# MCU_CTRL_MMR0_CFG0 register map
Vendor: Texas Instruments
Registers are 32-bit, read-write, reset 0x0 unless marked. A register's access mark holds for its fields unless they carry their own. Offsets are as the file gives them; [hi:lo] are bit positions; lines under a group give offsets from that group; {n}, {i} and the like mark numbered series.

## MCU_CTRL_MMR0_CFG0 (part 2 of 2)
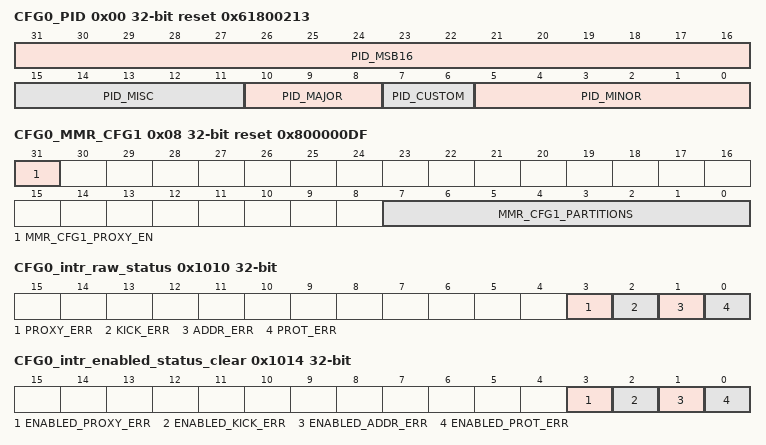
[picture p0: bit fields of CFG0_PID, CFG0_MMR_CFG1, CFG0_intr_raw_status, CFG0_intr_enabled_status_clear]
0x00 CFG0_PID ro reset 0x61800213
  [31:16] PID_MSB16, [15:11] PID_MISC, [10:8] PID_MAJOR, [7:6] PID_CUSTOM, [5:0] PID_MINOR
0x08 CFG0_MMR_CFG1 ro reset 0x800000DF
  [31] MMR_CFG1_PROXY_EN — Proxy addressing actived
  [7:0] MMR_CFG1_PARTITIONS — Indicates present partitions
{0x1008+0x4000*i} CFG0_LOCK{i}_KICK0 (i=0..4)
  [31:0] LOCK{i}_KICK0 — - KICK0 component
{0x100C+0x4000*i} CFG0_LOCK{i}_KICK1 (i=0..4)
  [31:0] LOCK{i}_KICK1 — - KICK1 component
0x1010 CFG0_intr_raw_status access not given
  [3] PROXY_ERR — Proxy0 access violation error. Raw status is read. Write a 1 to set the status. Writing a 0 has no effect. (access R/W1TS)
  [2] KICK_ERR — Kick access violation error. Raw status is read. Write a 1 to set the status. Writing a 0 has no effect. (access R/W1TS)
  [1] ADDR_ERR — Addressing violation error. Raw status is read. Write a 1 to set the status. Writing a 0 has no effect. (access R/W1TS)
  [0] PROT_ERR — Protection violation error. Raw status is read. Write a 1 to set the status. Writing a 0 has no effect. (access R/W1TS)
0x1014 CFG0_intr_enabled_status_clear access not given
  [3] ENABLED_PROXY_ERR — Proxy0 access violation error. Enabled status is read. Write a 1 to clear the status. Writing a 0 has no effect. (access R/W1TC)
  [2] ENABLED_KICK_ERR — Kick access violation error. Enabled status is read. Write a 1 to clear the status. Writing a 0 has no effect. (access R/W1TC)
  [1] ENABLED_ADDR_ERR — Addressing violation error. Enabled status is read. Write a 1 to clear the status. Writing a 0 has no effect. (access R/W1TC)
  [0] ENABLED_PROT_ERR — Protection violation error. Enabled status is read. Write a 1 to clear the status. Writing a 0 has no effect. (access R/W1TC)
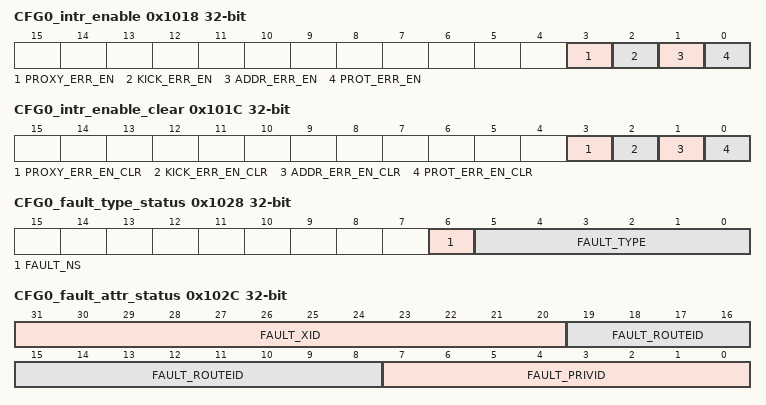
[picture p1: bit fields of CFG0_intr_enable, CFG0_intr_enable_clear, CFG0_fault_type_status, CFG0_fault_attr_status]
0x1018 CFG0_intr_enable access not given
  [3] PROXY_ERR_EN — Proxy0 access violation error enable. Write a 1 to set the enable. Writing a 0 has no effect. (access R/W1TS)
  [2] KICK_ERR_EN — Kick access violation error enable. Write a 1 to set the enable. Writing a 0 has no effect. (access R/W1TS)
  [1] ADDR_ERR_EN — Addressing violation error enable. Write a 1 to set the enable. Writing a 0 has no effect. (access R/W1TS)
  [0] PROT_ERR_EN — Protection violation error enable. Write a 1 to set the enable. Writing a 0 has no effect. (access R/W1TS)
0x101C CFG0_intr_enable_clear access not given
  [3] PROXY_ERR_EN_CLR — Proxy0 access violation error enable clear. Write a 1 to clear the enable. Writing a 0 has no effect. (access R/W1TC)
  [2] KICK_ERR_EN_CLR — Kick access violation error enable clear. Write a 1 to clear the enable. Writing a 0 has no effect. (access R/W1TC)
  [1] ADDR_ERR_EN_CLR — Addressing violation error enable clear. Write a 1 to clear the enable. Writing a 0 has no effect. (access R/W1TC)
  [0] PROT_ERR_EN_CLR — Protection violation error enable clear. Write a 1 to clear the enable. Writing a 0 has no effect. (access R/W1TC)
0x1020 CFG0_eoi
  [7:0] EOI_VECTOR — EOI vector value. Write this with interrupt distribution value in the chip.
0x1024 CFG0_fault_address ro
  [31:0] FAULT_ADDR — Fault Address.
0x1028 CFG0_fault_type_status ro
  [6] FAULT_NS — Non-secure access.
  [5:0] FAULT_TYPE — Fault Type 10_0000 = Supervisor read fault - priv = 1 dir = 1 dtype != 1 01_0000 = Supervisor write fault - priv = 1 dir = 0 00_1000 = Supervisor execute fault - priv = 1 dir = 1 dtype = 1 00_0100 = User read fault - priv = 0 dir = 1 dtype = 1 00_0010 = User write fault - priv = 0 dir = 0 00_0001 = User execute fault - priv = 0 dir = 1 dtype = 1 00_0000 = No fault
0x102C CFG0_fault_attr_status ro
  [31:20] FAULT_XID — XID.
  [19:8] FAULT_ROUTEID — Route ID.
  [7:0] FAULT_PRIVID — Privilege ID.
0x1030 CFG0_fault_clear wo
  [0] FAULT_CLR — Fault clear. Writing a 1 clears the current fault. Writing a 0 has no effect.
0x1100 CFG0_CLAIMREG_P0_R0_READONLY ro
  [31:0] CLAIMREG_P0_R0_READONLY — Claim bits for Partition 0
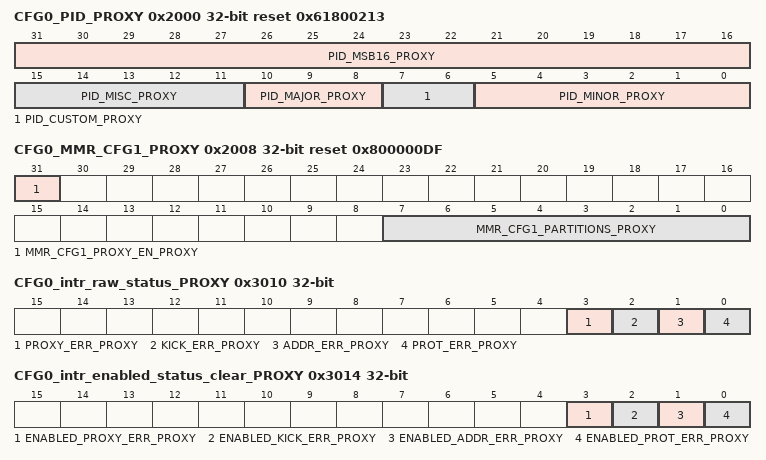
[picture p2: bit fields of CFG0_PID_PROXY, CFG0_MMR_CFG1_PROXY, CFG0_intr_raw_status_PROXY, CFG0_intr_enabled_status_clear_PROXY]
0x2000 CFG0_PID_PROXY ro reset 0x61800213
  [31:16] PID_MSB16_PROXY, [15:11] PID_MISC_PROXY, [10:8] PID_MAJOR_PROXY, [7:6] PID_CUSTOM_PROXY, [5:0] PID_MINOR_PROXY
0x2008 CFG0_MMR_CFG1_PROXY ro reset 0x800000DF
  [31] MMR_CFG1_PROXY_EN_PROXY — Proxy addressing actived
  [7:0] MMR_CFG1_PARTITIONS_PROXY — Indicates present partitions
{0x3008+0x4000*i} CFG0_LOCK{i}_KICK0_PROXY (i=0..4)
  [31:0] LOCK{i}_KICK0_PROXY — - KICK0 component
{0x300C+0x4000*i} CFG0_LOCK{i}_KICK1_PROXY (i=0..4)
  [31:0] LOCK{i}_KICK1_PROXY — - KICK1 component
0x3010 CFG0_intr_raw_status_PROXY access not given
  [3] PROXY_ERR_PROXY — Proxy0 access violation error. Raw status is read. Write a 1 to set the status. Writing a 0 has no effect. (access R/W1TS)
  [2] KICK_ERR_PROXY — Kick access violation error. Raw status is read. Write a 1 to set the status. Writing a 0 has no effect. (access R/W1TS)
  [1] ADDR_ERR_PROXY — Addressing violation error. Raw status is read. Write a 1 to set the status. Writing a 0 has no effect. (access R/W1TS)
  [0] PROT_ERR_PROXY — Protection violation error. Raw status is read. Write a 1 to set the status. Writing a 0 has no effect. (access R/W1TS)
0x3014 CFG0_intr_enabled_status_clear_PROXY access not given
  [3] ENABLED_PROXY_ERR_PROXY — Proxy0 access violation error. Enabled status is read. Write a 1 to clear the status. Writing a 0 has no effect. (access R/W1TC)
  [2] ENABLED_KICK_ERR_PROXY — Kick access violation error. Enabled status is read. Write a 1 to clear the status. Writing a 0 has no effect. (access R/W1TC)
  [1] ENABLED_ADDR_ERR_PROXY — Addressing violation error. Enabled status is read. Write a 1 to clear the status. Writing a 0 has no effect. (access R/W1TC)
  [0] ENABLED_PROT_ERR_PROXY — Protection violation error. Enabled status is read. Write a 1 to clear the status. Writing a 0 has no effect. (access R/W1TC)
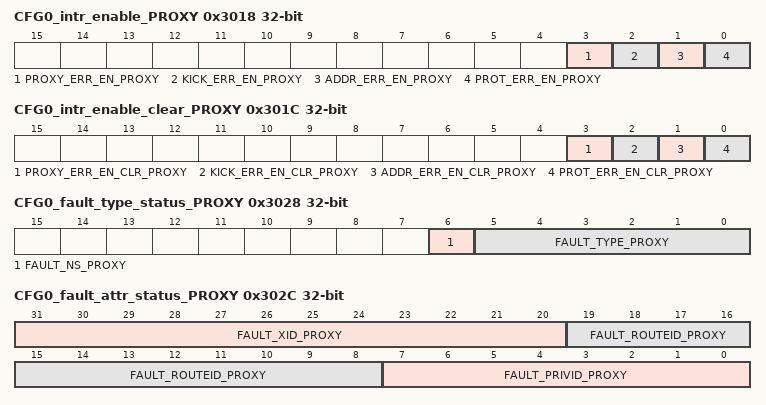
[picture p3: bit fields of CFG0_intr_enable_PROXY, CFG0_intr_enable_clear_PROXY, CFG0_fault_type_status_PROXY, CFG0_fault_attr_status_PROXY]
0x3018 CFG0_intr_enable_PROXY access not given
  [3] PROXY_ERR_EN_PROXY — Proxy0 access violation error enable. Write a 1 to set the enable. Writing a 0 has no effect. (access R/W1TS)
  [2] KICK_ERR_EN_PROXY — Kick access violation error enable. Write a 1 to set the enable. Writing a 0 has no effect. (access R/W1TS)
  [1] ADDR_ERR_EN_PROXY — Addressing violation error enable. Write a 1 to set the enable. Writing a 0 has no effect. (access R/W1TS)
  [0] PROT_ERR_EN_PROXY — Protection violation error enable. Write a 1 to set the enable. Writing a 0 has no effect. (access R/W1TS)
0x301C CFG0_intr_enable_clear_PROXY access not given
  [3] PROXY_ERR_EN_CLR_PROXY — Proxy0 access violation error enable clear. Write a 1 to clear the enable. Writing a 0 has no effect. (access R/W1TC)
  [2] KICK_ERR_EN_CLR_PROXY — Kick access violation error enable clear. Write a 1 to clear the enable. Writing a 0 has no effect. (access R/W1TC)
  [1] ADDR_ERR_EN_CLR_PROXY — Addressing violation error enable clear. Write a 1 to clear the enable. Writing a 0 has no effect. (access R/W1TC)
  [0] PROT_ERR_EN_CLR_PROXY — Protection violation error enable clear. Write a 1 to clear the enable. Writing a 0 has no effect. (access R/W1TC)
0x3020 CFG0_eoi_PROXY
  [7:0] EOI_VECTOR_PROXY — EOI vector value. Write this with interrupt distribution value in the chip.
0x3024 CFG0_fault_address_PROXY ro
  [31:0] FAULT_ADDR_PROXY — Fault Address.
0x3028 CFG0_fault_type_status_PROXY ro
  [6] FAULT_NS_PROXY — Non-secure access.
  [5:0] FAULT_TYPE_PROXY — Fault Type 10_0000 = Supervisor read fault - priv = 1 dir = 1 dtype != 1 01_0000 = Supervisor write fault - priv = 1 dir = 0 00_1000 = Supervisor execute fault - priv = 1 dir = 1 dtype = 1 00_0100 = User read fault - priv = 0 dir = 1 dtype = 1 00_0010 = User write fault - priv = 0 dir = 0 00_0001 = User execute fault - priv = 0 dir = 1 dtype = 1 00_0000 = No fault
0x302C CFG0_fault_attr_status_PROXY ro
  [31:20] FAULT_XID_PROXY — XID.
  [19:8] FAULT_ROUTEID_PROXY — Route ID.
  [7:0] FAULT_PRIVID_PROXY — Privilege ID.
0x3030 CFG0_fault_clear_PROXY wo
  [0] FAULT_CLR_PROXY — Fault clear. Writing a 1 clears the current fault. Writing a 0 has no effect.
0x3100 CFG0_CLAIMREG_P0_R0
  [31:0] CLAIMREG_P0_R0 — Claim bits for Partition 0
{0x4080+4i} CFG0_DBOUNCE_CFG{i} (i=1..6)
  [5:0] DBOUNCE_CFG{i}_DB_CFG — Configures the debounce period used for I/Os with debounce_sel{i} actived. See the AM64xx IO Integration Spec for Detail (https://pds.design.ti.com/cgi-bin/viewdocs?pds_bgid=21&docconfigid=736&filtertitle=2622&filteritem=13912)
0x40A0 CFG0_TEMP_DIODE_TRIM ro
  [13:0] TEMP_DIODE_TRIM_TRIM — Sets the diode non-ideality factor (n), starting from 100th place decimal and going down
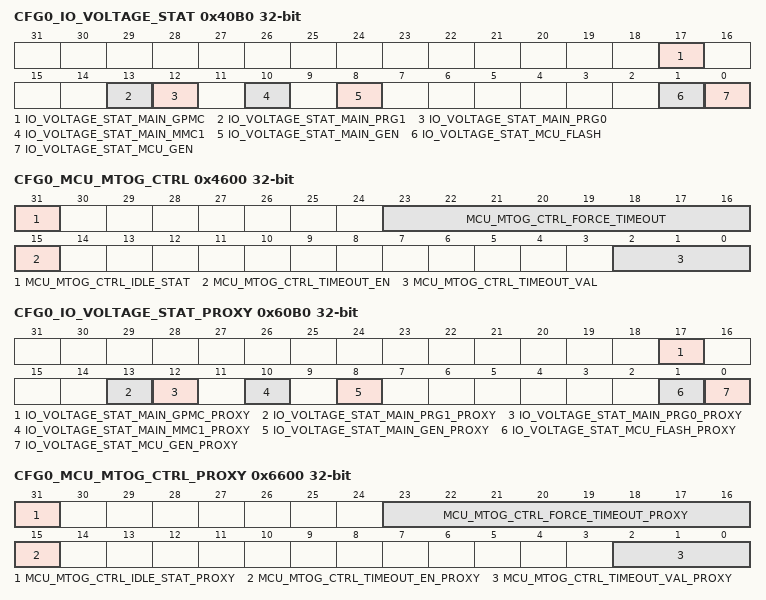
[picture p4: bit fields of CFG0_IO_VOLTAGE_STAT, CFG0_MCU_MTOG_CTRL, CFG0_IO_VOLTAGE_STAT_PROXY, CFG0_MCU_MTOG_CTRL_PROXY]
0x40B0 CFG0_IO_VOLTAGE_STAT ro
  [17] IO_VOLTAGE_STAT_MAIN_GPMC — Indicates the voltage for the GPMC I/O group (VDDSHV3)
  [13] IO_VOLTAGE_STAT_MAIN_PRG1 — Indicates the voltage for the PRG1 I/O group (VDDSHV1)
  [12] IO_VOLTAGE_STAT_MAIN_PRG0 — Indicates the voltage for the PRG0 I/O group (VDDSHV2)
  [10] IO_VOLTAGE_STAT_MAIN_MMC1 — Indicates the voltage for the MMC1 I/O group (VDDSHV5)
  [8] IO_VOLTAGE_STAT_MAIN_GEN — Indicates the voltage for the General I/O group (VDDSHV0)
  [1] IO_VOLTAGE_STAT_MCU_FLASH — Indicates the voltage for the Flash I/O group (VDDSHV4)
  [0] IO_VOLTAGE_STAT_MCU_GEN — Indicates the voltage for the MCU General I/O group (VDDSHV0_MCU)
0x4204 CFG0_MCU_TIMER1_CTRL
  [8] MCU_TIMER1_CTRL_CASCADE_EN — Actives cascading of TIMER1 to TIMER0
0x420C CFG0_MCU_TIMER3_CTRL
  [8] MCU_TIMER3_CTRL_CASCADE_EN — Actives cascading of TIMER3 to TIMER2
0x42E0 CFG0_MCU_I2C0_CTRL
  [0] MCU_I2C0_CTRL_HS_MCS_EN — HS Mode controller current source active.
0x4600 CFG0_MCU_MTOG_CTRL access per field
  [31] MCU_MTOG_CTRL_IDLE_STAT ro — Idle Status:
  [23:16] MCU_MTOG_CTRL_FORCE_TIMEOUT rw — Force Timout
  [15] MCU_MTOG_CTRL_TIMEOUT_EN rw — Timeout Active
  [2:0] MCU_MTOG_CTRL_TIMEOUT_VAL rw — Gasket Timeout Value
{0x5100+4i} CFG0_CLAIMREG_P1_R{i}_READONLY ro (i=0..12)
  [31:0] CLAIMREG_P1_R{i}_READONLY — Claim bits for Partition 1
{0x6080+4i} CFG0_DBOUNCE_CFG{i}_PROXY (i=1..6)
  [5:0] DBOUNCE_CFG{i}_DB_CFG_PROXY — Configures the debounce period used for I/Os with debounce_sel{i} actived. See the AM64xx IO Integration Spec for Detail (https://pds.design.ti.com/cgi-bin/viewdocs?pds_bgid=21&docconfigid=736&filtertitle=2622&filteritem=13912)
0x60A0 CFG0_TEMP_DIODE_TRIM_PROXY ro
  [13:0] TEMP_DIODE_TRIM_TRIM_PROXY — Sets the diode non-ideality factor (n), starting from 100th place decimal and going down
0x60B0 CFG0_IO_VOLTAGE_STAT_PROXY ro
  [17] IO_VOLTAGE_STAT_MAIN_GPMC_PROXY — Indicates the voltage for the GPMC I/O group (VDDSHV3)
  [13] IO_VOLTAGE_STAT_MAIN_PRG1_PROXY — Indicates the voltage for the PRG1 I/O group (VDDSHV1)
  [12] IO_VOLTAGE_STAT_MAIN_PRG0_PROXY — Indicates the voltage for the PRG0 I/O group (VDDSHV2)
  [10] IO_VOLTAGE_STAT_MAIN_MMC1_PROXY — Indicates the voltage for the MMC1 I/O group (VDDSHV5)
  [8] IO_VOLTAGE_STAT_MAIN_GEN_PROXY — Indicates the voltage for the General I/O group (VDDSHV0)
  [1] IO_VOLTAGE_STAT_MCU_FLASH_PROXY — Indicates the voltage for the Flash I/O group (VDDSHV4)
  [0] IO_VOLTAGE_STAT_MCU_GEN_PROXY — Indicates the voltage for the MCU General I/O group (VDDSHV0_MCU)
0x6204 CFG0_MCU_TIMER1_CTRL_PROXY
  [8] MCU_TIMER1_CTRL_CASCADE_EN_PROXY — Actives cascading of TIMER1 to TIMER0
0x620C CFG0_MCU_TIMER3_CTRL_PROXY
  [8] MCU_TIMER3_CTRL_CASCADE_EN_PROXY — Actives cascading of TIMER3 to TIMER2
0x62E0 CFG0_MCU_I2C0_CTRL_PROXY
  [0] MCU_I2C0_CTRL_HS_MCS_EN_PROXY — HS Mode controller current source active.
0x6600 CFG0_MCU_MTOG_CTRL_PROXY access per field
  [31] MCU_MTOG_CTRL_IDLE_STAT_PROXY ro — Idle Status:
  [23:16] MCU_MTOG_CTRL_FORCE_TIMEOUT_PROXY rw — Force Timout
  [15] MCU_MTOG_CTRL_TIMEOUT_EN_PROXY rw — Timeout Active
  [2:0] MCU_MTOG_CTRL_TIMEOUT_VAL_PROXY rw — Gasket Timeout Value
{0x7100+4i} CFG0_CLAIMREG_P1_R{i} (i=0..12)
  [31:0] CLAIMREG_P1_R{i} — Claim bits for Partition 1
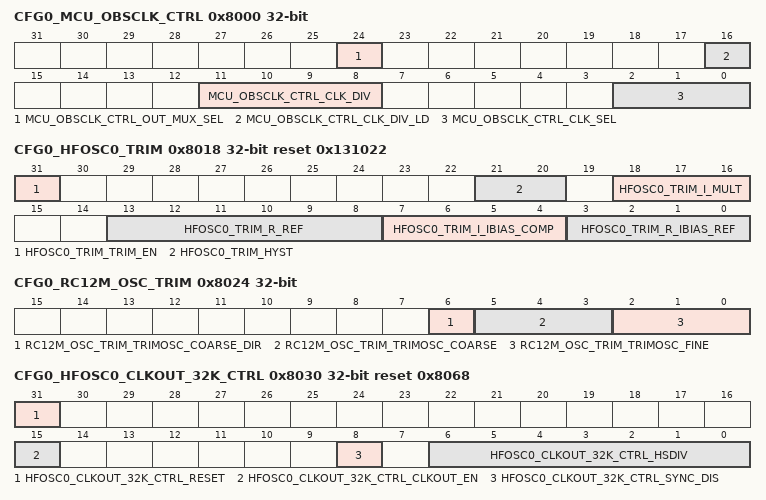
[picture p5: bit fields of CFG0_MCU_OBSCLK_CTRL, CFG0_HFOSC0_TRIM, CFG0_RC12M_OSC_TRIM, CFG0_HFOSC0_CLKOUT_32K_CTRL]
0x8000 CFG0_MCU_OBSCLK_CTRL
  [24] MCU_OBSCLK_CTRL_OUT_MUX_SEL — MCU_OBSCLK pin output mux selection.
  [16] MCU_OBSCLK_CTRL_CLK_DIV_LD — Load the output divider value
  [11:8] MCU_OBSCLK_CTRL_CLK_DIV — MCU_OBSCLK pin clock selection output divider
  [2:0] MCU_OBSCLK_CTRL_CLK_SEL — MCU_OBSCLK pin clock selection
0x8010 CFG0_HFOSC0_CTRL
  [4] HFOSC0_CTRL_BP_C — Oscillator bypass control. When set oscillator is in bypass mode
0x8018 CFG0_HFOSC0_TRIM reset 0x131022
  [31] HFOSC0_TRIM_TRIM_EN — Apply MMR values to OSC trim inputs instead of tie-offs
  [21:20] HFOSC0_TRIM_HYST — Sets comparator hysterisis
  [18:16] HFOSC0_TRIM_I_MULT — AGC AMP current multiplication gain
  [13:8] HFOSC0_TRIM_R_REF — Sets the AMP AGC bias current
  [7:4] HFOSC0_TRIM_I_IBIAS_COMP — Sets the COMP bias current
  [3:0] HFOSC0_TRIM_R_IBIAS_REF — Sets the base IBIAS reference
0x8024 CFG0_RC12M_OSC_TRIM
  [6] RC12M_OSC_TRIM_TRIMOSC_COARSE_DIR — Coarse adjustment direction. If output is greater than 12.5
  [5:3] RC12M_OSC_TRIM_TRIMOSC_COARSE — Coarse adjustment. Frequency is decreased or increased by 1.25 MHz per value based on the trimosc_coarse_dir value.
  [2:0] RC12M_OSC_TRIM_TRIMOSC_FINE — Fine adjustment. Decreases the frequency by 250 KHz per value.
0x8030 CFG0_HFOSC0_CLKOUT_32K_CTRL reset 0x8068
  [31] HFOSC0_CLKOUT_32K_CTRL_RESET — Asynchronous Divider Reset
  [15] HFOSC0_CLKOUT_32K_CTRL_CLKOUT_EN — HFOSC0_CLKOUT_32K active:
  [8] HFOSC0_CLKOUT_32K_CTRL_SYNC_DIS — HFOSC0_CLKOUT_32K Synchronize Deactivate
  [6:0] HFOSC0_CLKOUT_32K_CTRL_HSDIV — HFOSC0_CLKOUT_32K divider:
0x8040 CFG0_MCU_M4FSS_CLKSEL
  [0] MCU_M4FSS_CLKSEL_M4FSS_CLKSEL — Selects the Clock Divider for M4FSS
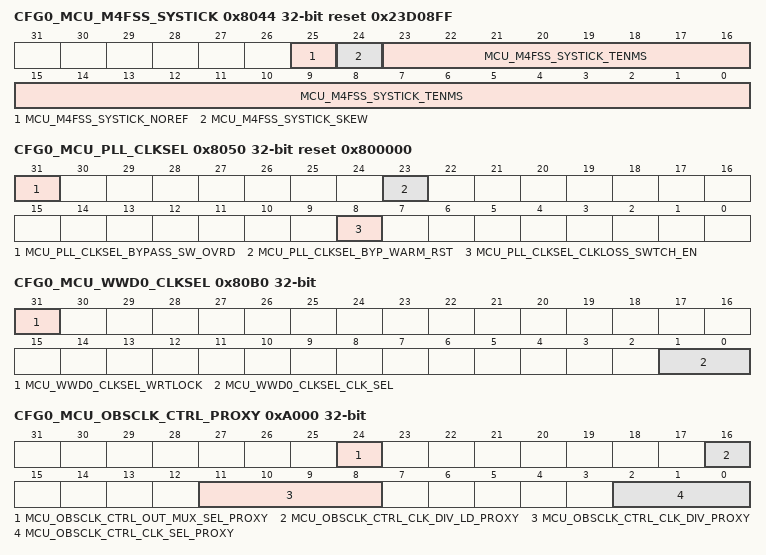
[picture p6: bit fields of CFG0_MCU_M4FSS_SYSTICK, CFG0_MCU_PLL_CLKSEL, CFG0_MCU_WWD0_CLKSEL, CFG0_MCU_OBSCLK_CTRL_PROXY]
0x8044 CFG0_MCU_M4FSS_SYSTICK access per field reset 0x23D08FF
  [25] MCU_M4FSS_SYSTICK_NOREF ro — No External Reference Clock for SysTick is available
  [24] MCU_M4FSS_SYSTICK_SKEW rw — Indicates whether or not the M4FSS free running clock divided by TENMS produces a 100Hz tick exactly
  [23:0] MCU_M4FSS_SYSTICK_TENMS rw — Integer Divider Value that produces a 100Hz SysTick from the M4FSS Clock Frequency. Default is 3,999,999 (4M - 1) to produce a 100Hz clock from a 400 MHz M4FSS Clock.
0x8050 CFG0_MCU_PLL_CLKSEL reset 0x800000
  [31] MCU_PLL_CLKSEL_BYPASS_SW_OVRD — PLL Bypass warm reset software override
  [23] MCU_PLL_CLKSEL_BYP_WARM_RST — PLL bypass mode after warm reset.
  [8] MCU_PLL_CLKSEL_CLKLOSS_SWTCH_EN — When set, actives automatic switching of MCU PLL[2:0] clock source to CLK_12M_RC if HFOSC0 clock loss is detected
{0x8060+4i} CFG0_MCU_TIMER{i}_CLKSEL (i=0..3)
  [2:0] MCU_TIMER{i}_CLKSEL_CLK_SEL — Timer functional clock input select mux control (Reserved values default to HFOSC1_CLK)
0x80A0 CFG0_MCU_SPI0_CLKSEL
  [16] MCU_SPI0_CLKSEL_MSTR_LB_CLKSEL — Controller mode receive capture clock loopback selection
0x80A4 CFG0_MCU_SPI1_CLKSEL
  [16] MCU_SPI1_CLKSEL_MSTR_LB_CLKSEL — Controller mode receive capture clock loopback selection
0x80B0 CFG0_MCU_WWD0_CLKSEL
  [31] MCU_WWD0_CLKSEL_WRTLOCK — When set, locks WWD0_CLKSEL from further writes until the next module reset.
  [1:0] MCU_WWD0_CLKSEL_CLK_SEL — Windowed watchdog timer functional clock input select mux control
0x80D0 CFG0_DDR16SS_PMCTRL
  [3:0] DDR16SS_PMCTRL_DATA_RETENTION — DDR16SS Retention:
0x9100 CFG0_CLAIMREG_P2_R0_READONLY ro
  [31:0] CLAIMREG_P2_R0_READONLY — Claim bits for Partition 2
0x9104 CFG0_CLAIMREG_P2_R1_READONLY ro
  [31:0] CLAIMREG_P2_R1_READONLY — Claim bits for Partition 2
0xA000 CFG0_MCU_OBSCLK_CTRL_PROXY
  [24] MCU_OBSCLK_CTRL_OUT_MUX_SEL_PROXY — MCU_OBSCLK pin output mux selection.
  [16] MCU_OBSCLK_CTRL_CLK_DIV_LD_PROXY — Load the output divider value
  [11:8] MCU_OBSCLK_CTRL_CLK_DIV_PROXY — MCU_OBSCLK pin clock selection output divider
  [2:0] MCU_OBSCLK_CTRL_CLK_SEL_PROXY — MCU_OBSCLK pin clock selection
0xA010 CFG0_HFOSC0_CTRL_PROXY
  [4] HFOSC0_CTRL_BP_C_PROXY — Oscillator bypass control. When set oscillator is in bypass mode
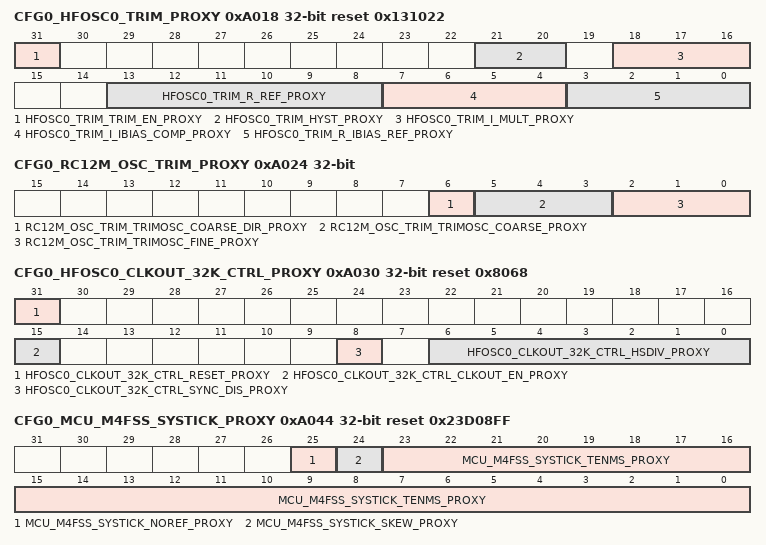
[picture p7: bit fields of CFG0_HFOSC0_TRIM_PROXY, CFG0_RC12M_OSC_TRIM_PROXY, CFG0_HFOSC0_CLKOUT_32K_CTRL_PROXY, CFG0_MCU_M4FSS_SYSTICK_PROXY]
0xA018 CFG0_HFOSC0_TRIM_PROXY reset 0x131022
  [31] HFOSC0_TRIM_TRIM_EN_PROXY — Apply MMR values to OSC trim inputs instead of tie-offs
  [21:20] HFOSC0_TRIM_HYST_PROXY — Sets comparator hysterisis
  [18:16] HFOSC0_TRIM_I_MULT_PROXY — AGC AMP current multiplication gain
  [13:8] HFOSC0_TRIM_R_REF_PROXY — Sets the AMP AGC bias current
  [7:4] HFOSC0_TRIM_I_IBIAS_COMP_PROXY — Sets the COMP bias current
  [3:0] HFOSC0_TRIM_R_IBIAS_REF_PROXY — Sets the base IBIAS reference
0xA024 CFG0_RC12M_OSC_TRIM_PROXY
  [6] RC12M_OSC_TRIM_TRIMOSC_COARSE_DIR_PROXY — Coarse adjustment direction. If output is greater than 12.5
  [5:3] RC12M_OSC_TRIM_TRIMOSC_COARSE_PROXY — Coarse adjustment. Frequency is decreased or increased by 1.25 MHz per value based on the trimosc_coarse_dir value.
  [2:0] RC12M_OSC_TRIM_TRIMOSC_FINE_PROXY — Fine adjustment. Decreases the frequency by 250 KHz per value.
0xA030 CFG0_HFOSC0_CLKOUT_32K_CTRL_PROXY reset 0x8068
  [31] HFOSC0_CLKOUT_32K_CTRL_RESET_PROXY — Asynchronous Divider Reset
  [15] HFOSC0_CLKOUT_32K_CTRL_CLKOUT_EN_PROXY — HFOSC0_CLKOUT_32K active:
  [8] HFOSC0_CLKOUT_32K_CTRL_SYNC_DIS_PROXY — HFOSC0_CLKOUT_32K Synchronize Deactivate
  [6:0] HFOSC0_CLKOUT_32K_CTRL_HSDIV_PROXY — HFOSC0_CLKOUT_32K divider:
0xA040 CFG0_MCU_M4FSS_CLKSEL_PROXY
  [0] MCU_M4FSS_CLKSEL_M4FSS_CLKSEL_PROXY — Selects the Clock Divider for M4FSS
0xA044 CFG0_MCU_M4FSS_SYSTICK_PROXY access per field reset 0x23D08FF
  [25] MCU_M4FSS_SYSTICK_NOREF_PROXY ro — No External Reference Clock for SysTick is available
  [24] MCU_M4FSS_SYSTICK_SKEW_PROXY rw — Indicates whether or not the M4FSS free running clock divided by TENMS produces a 100Hz tick exactly
  [23:0] MCU_M4FSS_SYSTICK_TENMS_PROXY rw — Integer Divider Value that produces a 100Hz SysTick from the M4FSS Clock Frequency. Default is 3,999,999 (4M - 1) to produce a 100Hz clock from a 400 MHz M4FSS Clock.
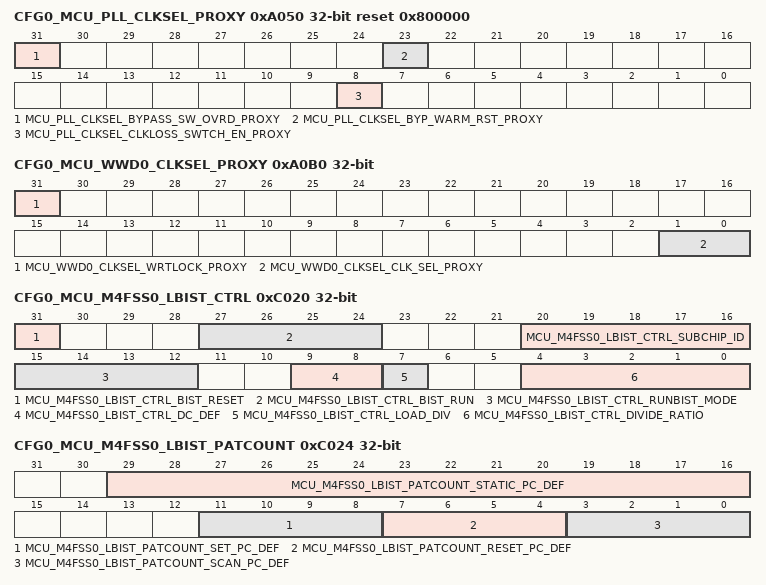
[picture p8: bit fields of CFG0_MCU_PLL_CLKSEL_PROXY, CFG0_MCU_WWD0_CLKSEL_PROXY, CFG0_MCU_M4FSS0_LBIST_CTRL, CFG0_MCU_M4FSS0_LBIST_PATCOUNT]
0xA050 CFG0_MCU_PLL_CLKSEL_PROXY reset 0x800000
  [31] MCU_PLL_CLKSEL_BYPASS_SW_OVRD_PROXY — PLL Bypass warm reset software override
  [23] MCU_PLL_CLKSEL_BYP_WARM_RST_PROXY — PLL bypass mode after warm reset.
  [8] MCU_PLL_CLKSEL_CLKLOSS_SWTCH_EN_PROXY — When set, actives automatic switching of MCU PLL[2:0] clock source to CLK_12M_RC if HFOSC0 clock loss is detected
{0xA060+4i} CFG0_MCU_TIMER{i}_CLKSEL_PROXY (i=0..3)
  [2:0] MCU_TIMER{i}_CLKSEL_CLK_SEL_PROXY — Timer functional clock input select mux control (Reserved values default to HFOSC1_CLK)
0xA0A0 CFG0_MCU_SPI0_CLKSEL_PROXY
  [16] MCU_SPI0_CLKSEL_MSTR_LB_CLKSEL_PROXY — Controller mode receive capture clock loopback selection
0xA0A4 CFG0_MCU_SPI1_CLKSEL_PROXY
  [16] MCU_SPI1_CLKSEL_MSTR_LB_CLKSEL_PROXY — Controller mode receive capture clock loopback selection
0xA0B0 CFG0_MCU_WWD0_CLKSEL_PROXY
  [31] MCU_WWD0_CLKSEL_WRTLOCK_PROXY — When set, locks WWD0_CLKSEL from further writes until the next module reset.
  [1:0] MCU_WWD0_CLKSEL_CLK_SEL_PROXY — Windowed watchdog timer functional clock input select mux control
0xA0D0 CFG0_DDR16SS_PMCTRL_PROXY
  [3:0] DDR16SS_PMCTRL_DATA_RETENTION_PROXY — DDR16SS Retention:
0xB100 CFG0_CLAIMREG_P2_R0
  [31:0] CLAIMREG_P2_R0 — Claim bits for Partition 2
0xB104 CFG0_CLAIMREG_P2_R1
  [31:0] CLAIMREG_P2_R1 — Claim bits for Partition 2
0xC020 CFG0_MCU_M4FSS0_LBIST_CTRL
  [31] MCU_M4FSS0_LBIST_CTRL_BIST_RESET — This bitfield is not used. The bist_reset control for DMSC is generated by the POST state machine. The bitfield still reflects the efuse value.
  [27:24] MCU_M4FSS0_LBIST_CTRL_BIST_RUN — This bitfield is not used. The bist_run control for DMSC is generated by the POST state machine. The bitfield still reflects the efuse value.
  [20:16] MCU_M4FSS0_LBIST_CTRL_SUBCHIP_ID — Specifies which sub-chip is to be tested
  [15:12] MCU_M4FSS0_LBIST_CTRL_RUNBIST_MODE — Runbist mode active if all bits are 1
  [9:8] MCU_M4FSS0_LBIST_CTRL_DC_DEF — Clock delay after scan_active switching
  [7] MCU_M4FSS0_LBIST_CTRL_LOAD_DIV — Loads LBIST clock divide ratio on transition from 0 to 1
  [4:0] MCU_M4FSS0_LBIST_CTRL_DIVIDE_RATIO — LBIST clock divide ratio
0xC024 CFG0_MCU_M4FSS0_LBIST_PATCOUNT
  [29:16] MCU_M4FSS0_LBIST_PATCOUNT_STATIC_PC_DEF — Number of stuck-at patterns to run
  [11:8] MCU_M4FSS0_LBIST_PATCOUNT_SET_PC_DEF — Number of set patterns to run
  [7:4] MCU_M4FSS0_LBIST_PATCOUNT_RESET_PC_DEF — Number of reset patterns to run
  [3:0] MCU_M4FSS0_LBIST_PATCOUNT_SCAN_PC_DEF — Number of chain test patterns to run
0xC028 CFG0_MCU_M4FSS0_LBIST_SEED0
  [31:0] MCU_M4FSS0_LBIST_SEED0_PRPG_DEF — Initial seed for PRPG (bits 31:0)
0xC02C CFG0_MCU_M4FSS0_LBIST_SEED1
  [20:0] MCU_M4FSS0_LBIST_SEED1_PRPG_DEF — Initial seed for PRPG (bits 52:32)
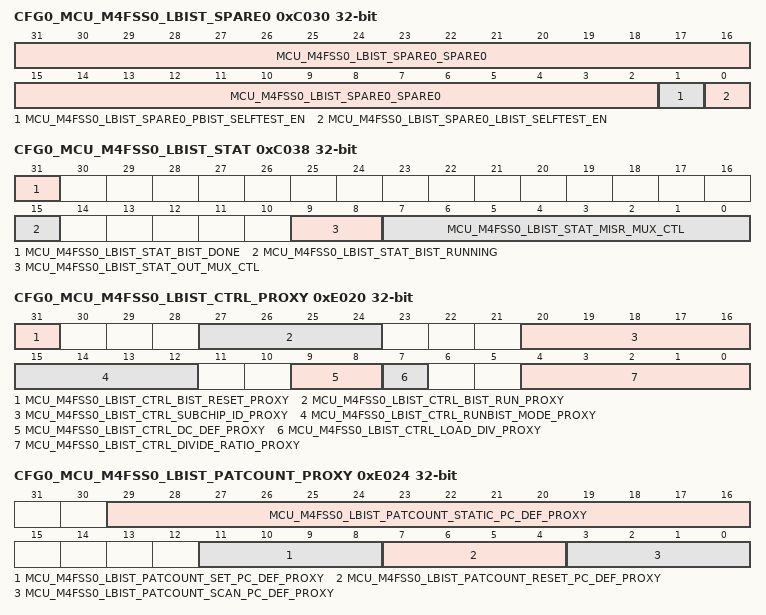
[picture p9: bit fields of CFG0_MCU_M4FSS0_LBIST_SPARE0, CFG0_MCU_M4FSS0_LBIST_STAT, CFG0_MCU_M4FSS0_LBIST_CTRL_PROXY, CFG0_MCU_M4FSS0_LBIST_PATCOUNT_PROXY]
0xC030 CFG0_MCU_M4FSS0_LBIST_SPARE0
  [31:2] MCU_M4FSS0_LBIST_SPARE0_SPARE0 — LBIST spare bits
  [1] MCU_M4FSS0_LBIST_SPARE0_PBIST_SELFTEST_EN — PBIST isolation control
  [0] MCU_M4FSS0_LBIST_SPARE0_LBIST_SELFTEST_EN — LBIST isolation control
0xC034 CFG0_MCU_M4FSS0_LBIST_SPARE1
  [31:0] MCU_M4FSS0_LBIST_SPARE1_SPARE1 — LBIST spare bits
0xC038 CFG0_MCU_M4FSS0_LBIST_STAT access per field
  [31] MCU_M4FSS0_LBIST_STAT_BIST_DONE ro — LBIST is done
  [15] MCU_M4FSS0_LBIST_STAT_BIST_RUNNING ro — LBIST is running
  [9:8] MCU_M4FSS0_LBIST_STAT_OUT_MUX_CTL rw — Selects source of LBIST output
  [7:0] MCU_M4FSS0_LBIST_STAT_MISR_MUX_CTL rw — Selects block of 32 MISR bits to read. A value of 0 selects a compacted 32-bit version of the full MISR. A value of 1-32 select a 32-bit segment of the MISR.
0xC03C CFG0_MCU_M4FSS0_LBIST_MISR ro
  [31:0] MCU_M4FSS0_LBIST_MISR_MISR_RESULT — 32-bits of MISR value selected by misr_mux_ctl
0xD100 CFG0_CLAIMREG_P3_R0_READONLY ro
  [31:0] CLAIMREG_P3_R0_READONLY — Claim bits for Partition 3
0xE020 CFG0_MCU_M4FSS0_LBIST_CTRL_PROXY
  [31] MCU_M4FSS0_LBIST_CTRL_BIST_RESET_PROXY — This bitfield is not used. The bist_reset control for DMSC is generated by the POST state machine. The bitfield still reflects the efuse value.
  [27:24] MCU_M4FSS0_LBIST_CTRL_BIST_RUN_PROXY — This bitfield is not used. The bist_run control for DMSC is generated by the POST state machine. The bitfield still reflects the efuse value.
  [20:16] MCU_M4FSS0_LBIST_CTRL_SUBCHIP_ID_PROXY — Specifies which sub-chip is to be tested
  [15:12] MCU_M4FSS0_LBIST_CTRL_RUNBIST_MODE_PROXY — Runbist mode active if all bits are 1
  [9:8] MCU_M4FSS0_LBIST_CTRL_DC_DEF_PROXY — Clock delay after scan_active switching
  [7] MCU_M4FSS0_LBIST_CTRL_LOAD_DIV_PROXY — Loads LBIST clock divide ratio on transition from 0 to 1
  [4:0] MCU_M4FSS0_LBIST_CTRL_DIVIDE_RATIO_PROXY — LBIST clock divide ratio
0xE024 CFG0_MCU_M4FSS0_LBIST_PATCOUNT_PROXY
  [29:16] MCU_M4FSS0_LBIST_PATCOUNT_STATIC_PC_DEF_PROXY — Number of stuck-at patterns to run
  [11:8] MCU_M4FSS0_LBIST_PATCOUNT_SET_PC_DEF_PROXY — Number of set patterns to run
  [7:4] MCU_M4FSS0_LBIST_PATCOUNT_RESET_PC_DEF_PROXY — Number of reset patterns to run
  [3:0] MCU_M4FSS0_LBIST_PATCOUNT_SCAN_PC_DEF_PROXY — Number of chain test patterns to run
0xE028 CFG0_MCU_M4FSS0_LBIST_SEED0_PROXY
  [31:0] MCU_M4FSS0_LBIST_SEED0_PRPG_DEF_PROXY — Initial seed for PRPG (bits 31:0)
0xE02C CFG0_MCU_M4FSS0_LBIST_SEED1_PROXY
  [20:0] MCU_M4FSS0_LBIST_SEED1_PRPG_DEF_PROXY — Initial seed for PRPG (bits 52:32)
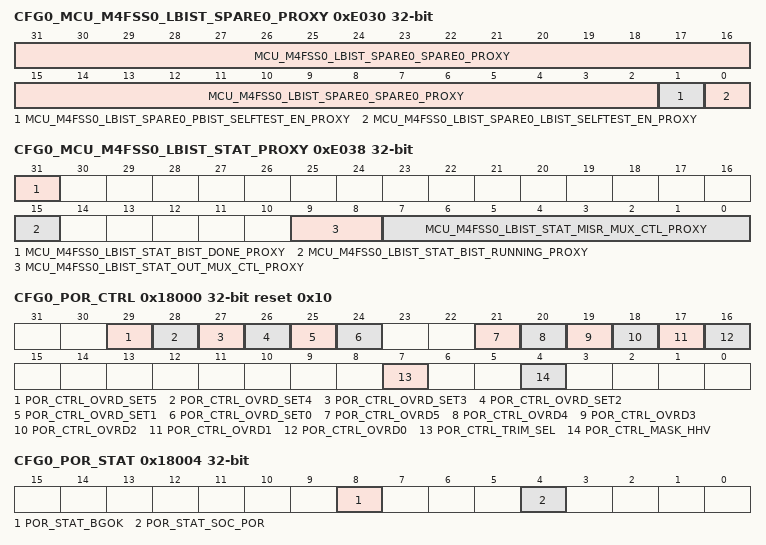
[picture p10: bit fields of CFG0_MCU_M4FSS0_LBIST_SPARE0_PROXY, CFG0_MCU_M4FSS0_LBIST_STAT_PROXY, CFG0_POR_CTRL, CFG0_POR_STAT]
0xE030 CFG0_MCU_M4FSS0_LBIST_SPARE0_PROXY
  [31:2] MCU_M4FSS0_LBIST_SPARE0_SPARE0_PROXY — LBIST spare bits
  [1] MCU_M4FSS0_LBIST_SPARE0_PBIST_SELFTEST_EN_PROXY — PBIST isolation control
  [0] MCU_M4FSS0_LBIST_SPARE0_LBIST_SELFTEST_EN_PROXY — LBIST isolation control
0xE034 CFG0_MCU_M4FSS0_LBIST_SPARE1_PROXY
  [31:0] MCU_M4FSS0_LBIST_SPARE1_SPARE1_PROXY — LBIST spare bits
0xE038 CFG0_MCU_M4FSS0_LBIST_STAT_PROXY access per field
  [31] MCU_M4FSS0_LBIST_STAT_BIST_DONE_PROXY ro — LBIST is done
  [15] MCU_M4FSS0_LBIST_STAT_BIST_RUNNING_PROXY ro — LBIST is running
  [9:8] MCU_M4FSS0_LBIST_STAT_OUT_MUX_CTL_PROXY rw — Selects source of LBIST output
  [7:0] MCU_M4FSS0_LBIST_STAT_MISR_MUX_CTL_PROXY rw — Selects block of 32 MISR bits to read. A value of 0 selects a compacted 32-bit version of the full MISR. A value of 1-32 select a 32-bit segment of the MISR.
0xE03C CFG0_MCU_M4FSS0_LBIST_MISR_PROXY ro
  [31:0] MCU_M4FSS0_LBIST_MISR_MISR_RESULT_PROXY — 32-bits of MISR value selected by misr_mux_ctl
0xF100 CFG0_CLAIMREG_P3_R0
  [31:0] CLAIMREG_P3_R0 — Claim bits for Partition 3
{0x11100+4i} CFG0_CLAIMREG_P4_R{i}_READONLY ro (i=0..14)
  [31:0] CLAIMREG_P4_R{i}_READONLY — Claim bits for Partition 4
{0x13100+4i} CFG0_CLAIMREG_P4_R{i} (i=0..14)
  [31:0] CLAIMREG_P4_R{i} — Claim bits for Partition 4
0x18000 CFG0_POR_CTRL reset 0x10
  [29] POR_CTRL_OVRD_SET5 — Reserved override set
  [28] POR_CTRL_OVRD_SET4 — POKLVB override set
  [27] POR_CTRL_OVRD_SET3 — POKLVA override set
  [26] POR_CTRL_OVRD_SET2 — POKHV override set
  [25] POR_CTRL_OVRD_SET1 — BGOK override set
  [24] POR_CTRL_OVRD_SET0 — PORHV override set
  [21] POR_CTRL_OVRD5 — Reserved override active
  [20] POR_CTRL_OVRD4 — POKLVB override active
  [19] POR_CTRL_OVRD3 — POKLVA override active
  [18] POR_CTRL_OVRD2 — POKHV override active
  [17] POR_CTRL_OVRD1 — BGOK override active
  [16] POR_CTRL_OVRD0 — PORHV override active
  [7] POR_CTRL_TRIM_SEL — POR Trim Select
  [4] POR_CTRL_MASK_HHV — Mask HHV/SOC_PORz outputs when applying new trim values
0x18004 CFG0_POR_STAT ro
  [8] POR_STAT_BGOK — Bandgap OK status
  [4] POR_STAT_SOC_POR — POR module status
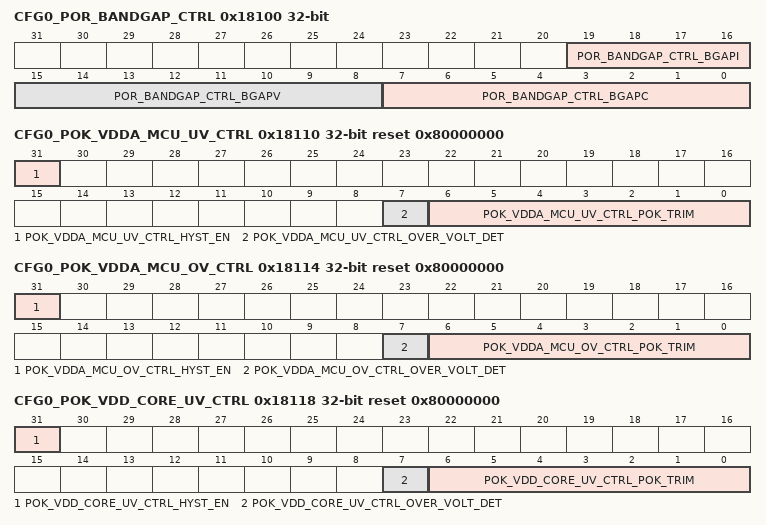
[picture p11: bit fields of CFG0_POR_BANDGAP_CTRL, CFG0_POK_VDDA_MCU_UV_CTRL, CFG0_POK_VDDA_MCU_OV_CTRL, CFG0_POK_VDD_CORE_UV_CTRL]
0x18100 CFG0_POR_BANDGAP_CTRL
  [19:16] POR_BANDGAP_CTRL_BGAPI — Bandgap output current trim bits
  [15:8] POR_BANDGAP_CTRL_BGAPV — Bandgap output voltage magnitude trim bits
  [7:0] POR_BANDGAP_CTRL_BGAPC — Bandgap slope trim bits. Bit7 is used to calculate the offset
0x18110 CFG0_POK_VDDA_MCU_UV_CTRL reset 0x80000000
  [31] POK_VDDA_MCU_UV_CTRL_HYST_EN — Active POK hysteresis
  [7] POK_VDDA_MCU_UV_CTRL_OVER_VOLT_DET — Over / under voltage detection mode
  [6:0] POK_VDDA_MCU_UV_CTRL_POK_TRIM — POK Trim Bits
0x18114 CFG0_POK_VDDA_MCU_OV_CTRL reset 0x80000000
  [31] POK_VDDA_MCU_OV_CTRL_HYST_EN — Active POK hysteresis
  [7] POK_VDDA_MCU_OV_CTRL_OVER_VOLT_DET — Over / under voltage detection mode
  [6:0] POK_VDDA_MCU_OV_CTRL_POK_TRIM — POK Trim Bits
0x18118 CFG0_POK_VDD_CORE_UV_CTRL reset 0x80000000
  [31] POK_VDD_CORE_UV_CTRL_HYST_EN — Active POK hysteresis
  [7] POK_VDD_CORE_UV_CTRL_OVER_VOLT_DET — Over / under voltage detection mode
  [6:0] POK_VDD_CORE_UV_CTRL_POK_TRIM — POK Trim Bits
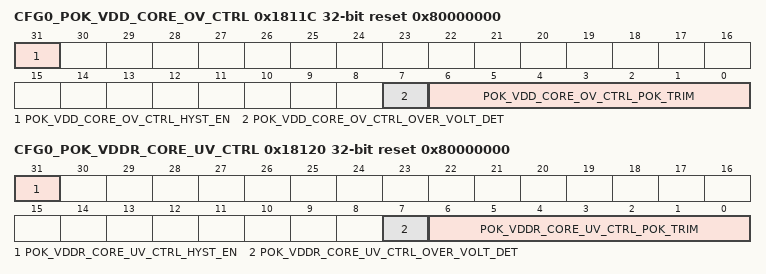
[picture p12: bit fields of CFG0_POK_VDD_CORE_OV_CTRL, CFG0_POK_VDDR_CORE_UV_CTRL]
0x1811C CFG0_POK_VDD_CORE_OV_CTRL reset 0x80000000
  [31] POK_VDD_CORE_OV_CTRL_HYST_EN — Active POK hysteresis
  [7] POK_VDD_CORE_OV_CTRL_OVER_VOLT_DET — Over / under voltage detection mode
  [6:0] POK_VDD_CORE_OV_CTRL_POK_TRIM — POK Trim Bits
0x18120 CFG0_POK_VDDR_CORE_UV_CTRL reset 0x80000000
  [31] POK_VDDR_CORE_UV_CTRL_HYST_EN — Active POK hysteresis
  [7] POK_VDDR_CORE_UV_CTRL_OVER_VOLT_DET — Over / under voltage detection mode
  [6:0] POK_VDDR_CORE_UV_CTRL_POK_TRIM — POK Trim Bits
